# STM32H755_CM7 register map
File version: 2.5
CPU: CM7 r0p1, little endian, MPU, FPU, 4 interrupt priority bits
Registers are 32-bit, read-write, reset 0x0 unless marked. A register's access mark holds for its fields unless they carry their own. Offsets are from the block's base; [hi:lo] are bit positions.

## RNG
Base 0x48021800
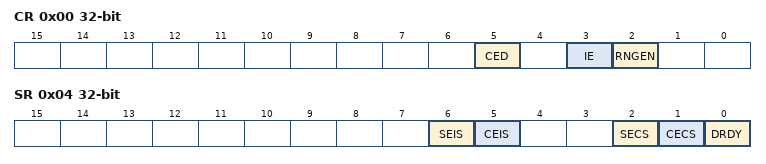
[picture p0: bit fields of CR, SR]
0x00 CR — RNG control register
  [5] CED — Clock error detection Note: The clock error detection can be used only when ck_rc48 or ck_pll1_q (ck_pll1_q = 48MHz) source is selected otherwise, CED bit must be equal to 1. The clock error detection cannot be enabled nor disabled on the fly when RNG peripheral is enabled, to enable or disable CED the RNG must be disabled.
    0=Enabled (Clock error detection is enabled); 1=Disabled (Clock error detection is disabled)
  [3] IE — Interrupt enable
    0=Disabled (RNG interrupt is disabled); 1=Enabled (RNG interrupt is enabled)
  [2] RNGEN — Random number generator enable
    0=Disabled (Random number generator is disabled); 1=Enabled (Random number generator is enabled)
0x04 SR access per field — RNG status register
  [6] SEIS rw write-0-clears — Seed error interrupt status This bit is set at the same time as SECS. It is cleared by writing it to 0. ** More than 64 consecutive bits at the same value (0 or 1) ** More than 32 consecutive alternances of 0 and 1 (0101010101...01) An interrupt is pending if IE = 1 in the RNG_CR register.
    on write: 0=Clear flag | on read: 0=No faulty sequence detected; 1=Fault (At least one faulty sequence has been detected. See **SECS** bit description for details. An interrupt is pending if IE = 1 in the RNG_CR register.)
  [5] CEIS rw write-0-clears — Clock error interrupt status This bit is set at the same time as CECS. It is cleared by writing it to 0. An interrupt is pending if IE = 1 in the RNG_CR register. Note: This bit is meaningless if CED (Clock error detection) bit in RNG_CR is equal to 1.
    on write: 0=Clear flag | on read: 0=Correct (The RNG clock is correct); 1=Slow (The RNG has been detected too slow An interrupt is pending if IE = 1 in the RNG_CR register)
  [2] SECS ro — Seed error current status ** More than 64 consecutive bits at the same value (0 or 1) ** More than 32 consecutive alternances of 0 and 1 (0101010101...01)
    0=No faulty sequence has currently been detected. If the SEIS bit is set, this means that a faulty sequence was detected and the situation has been recovered.; 1=Fault (At least one faulty sequence has been detected - see ref manual for details)
  [1] CECS ro — Clock error current status Note: This bit is meaningless if CED (Clock error detection) bit in RNG_CR is equal to 1.
    0=Correct (The RNG clock is correct. If the CEIS bit is set, this means that a slow clock was detected and the situation has been recovered.); 1=Slow (The RNG clock is too slow)
  [0] DRDY ro — Data ready Note: If IE=1 in RNG_CR, an interrupt is generated when DRDY=1. It can rise when the peripheral is disabled. When the output buffer becomes empty (after reading RNG_DR), this bit returns to 0 until a new random value is generated.
    0=Invalid (The RNG_DR register is not yet valid, no random data is available); 1=Valid (The RNG_DR register contains valid random data. Once the RNG_DR register has been read, this bit returns to 0 until a new random value is generated.)
0x08 DR ro — The RNG_DR register is a read-only register that delivers a 32-bit random value when read. The content of this register is valid when DRDY= 1, even if RNGEN=0.
  [31:0] RNDATA — Random data 32-bit random data which are valid when DRDY=1.

## VREFBUF
Base 0x58003C00
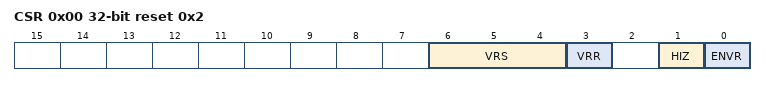
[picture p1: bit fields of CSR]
0x00 CSR access per field reset 0x2 — VREFBUF control and status register
  [6:4] VRS rw — Voltage reference scale These bits select the value generated by the voltage reference buffer. Other: Reserved
  [3] VRR ro — Voltage reference buffer ready
  [1] HIZ rw — High impedance mode This bit controls the analog switch to connect or not the VREF+ pin. Refer to Table196: VREF buffer modes for the mode descriptions depending on ENVR bit configuration.
  [0] ENVR rw — Voltage reference buffer mode enable This bit is used to enable the voltage reference buffer mode.
0x04 CCR — VREFBUF calibration control register
  [5:0] TRIM — Trimming code These bits are automatically initialized after reset with the trimming value stored in the Flash memory during the production test. Writing into these bits allows to tune the internal reference buffer voltage.
